AUTOSAR XML (schema 4.0)
package /Interfaces
  sender receiver interface IfWheelSpeed
    data WheelSpeed: type=uint16
  sender receiver interface IfBrakeTorque
    data BrakeTorqueRequest: type=float32
  client server interface IfDiag
    operation ReportEvent
package /Components
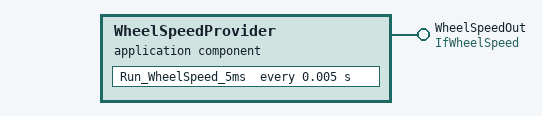
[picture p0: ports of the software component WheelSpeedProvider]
  application sw component type WheelSpeedProvider
    provide port WheelSpeedOut: provided-interface=IfWheelSpeed
    behavior Beh
      timing event T5: start-on-event=Run_WheelSpeed_5ms, period=0.005
      runnable Run_WheelSpeed_5ms
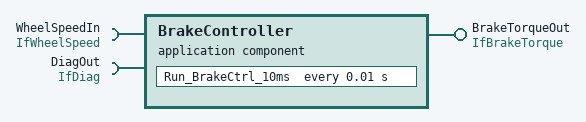
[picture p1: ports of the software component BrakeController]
  application sw component type BrakeController
    require port WheelSpeedIn: required-interface=IfWheelSpeed
    provide port BrakeTorqueOut: provided-interface=IfBrakeTorque
    require port DiagOut: required-interface=IfDiag
    behavior Beh
      timing event T10: start-on-event=Run_BrakeCtrl_10ms, period=0.01
      runnable Run_BrakeCtrl_10ms
  complex device driver sw component type ActuatorDriver
    require port TorqueIn: required-interface=IfBrakeTorque
  composition sw component type BrakeSystem
    component wsp: type=WheelSpeedProvider
    component bc: type=BrakeController
    component act: type=ActuatorDriver
    connect wsp.WheelSpeedOut -> bc.WheelSpeedIn
    connect bc.BrakeTorqueOut -> act.TorqueIn
